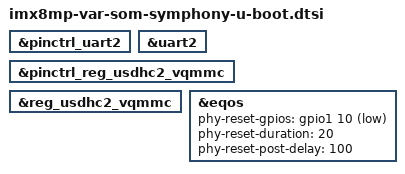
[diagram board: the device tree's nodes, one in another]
// SPDX-License-Identifier: GPL-2.0+
/*
 * Copyright 2019 NXP
 * Copyright 2020-2021 Variscite Ltd.
 */

#include "imx8mp-var-common-u-boot.dtsi"

&pinctrl_uart2 {
	u-boot,dm-spl;
};

&uart2 {
	u-boot,dm-spl;
};

&pinctrl_reg_usdhc2_vqmmc {
	u-boot,dm-spl;
};

&reg_usdhc2_vqmmc {
	u-boot,dm-spl;
};

&eqos {
	phy-reset-gpios = <&gpio1 10 GPIO_ACTIVE_LOW>;
	phy-reset-duration = <20>;
	phy-reset-post-delay = <100>;
};
